# ARMv8M-Baseline register map
Registers are read-only, no defined reset value unless marked. A register's access mark holds for its fields unless they carry their own. Offsets are from the block's base; [hi:lo] are bit positions; {n}, {i} and the like mark numbered series.

## SCB — System Control Block
Base 0xE000ED00
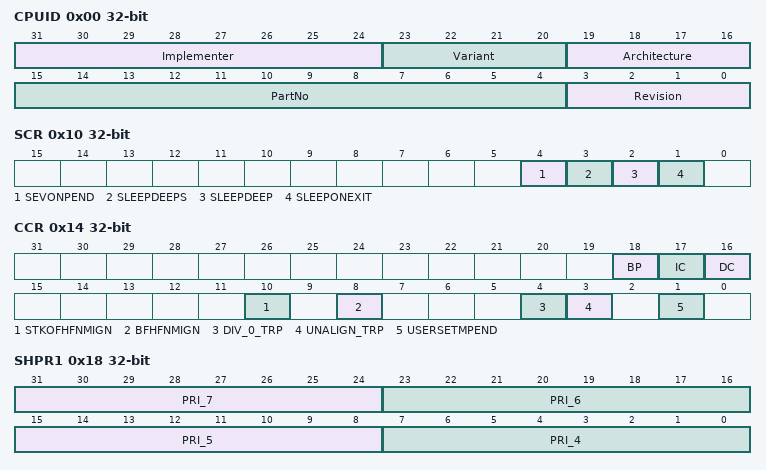
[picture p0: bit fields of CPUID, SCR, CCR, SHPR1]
0x00 CPUID — CPUID Base Register provides identification information for the PE, including an implementer code for the device and a device ID number
  [31:24] Implementer — Implementer code. This field must hold an implementer code that has been assigned by ARM
    65='A': ARM Limited
  [23:20] Variant — Variant number. IMPLEMENTATION DEFINED variant number
  [19:16] Architecture — Architecture version. Defines the Architecture implemented by the PE
    12=ARMv8-M architecture without Main Extension; 15=ARMv8-M architecture with Main Extension
  [15:4] PartNo — Part number. IMPLEMENTATION DEFINED primary part number for the device
  [3:0] Revision — Revision number. IMPLEMENTATION DEFINED revision number for the device
0x04 ICSR rw — Interrupt Control and State Register controls and provides status information for NMI, PendSV, SysTick and interrupts
  [31] PENDNMISET — Pend NMI set. Allows the NMI exception to be set as pending
    0=No effect; 1=Sets the NMI exception pending
  [31] PENDNMISET — Pend NMI set. Indicates whether the NMI exception is pending
    0=NMI exception not pending; 1=NMI exception pending
  [30] PENDNMICLR — Pend NMI clear. Allows the NMI exception pend state to be cleared
    0=No effect; 1=Clear pending status
  [28] PENDSVSET — Pend PendSV set. Allows the PendSV exception for the selected Security state to be set as pending
    0=No effect; 1=Sets the PendSV exception pending
  [28] PENDSVSET — Pend PendSV set. Indicates whether the PendSV for the selected Security state exception is pending
    0=PendSV exception not pending; 1=PendSV exception pending
  [27] PENDSVCLR — Pend PendSV clear
    0=No effect; 1=Clear pending status
  [26] PENDSTSET — Pend SysTick set. Allows the SysTick for the selected Security state exception to be set as pending
    0=No effect; 1=Sets the SysTick exception for the selected Security state pending
  [26] PENDSTSET — Pend SysTick set. Indicates whether the SysTick for the selected Security state exception is pending
    0=SysTick exception not pending; 1=SysTick exception pending
  [25] PENDSTCLR — Pend SysTick clear
    0=No effect; 1=Clear pending status
  [24] STTNS — SysTick Targets Non-secure
    0=SysTick is Secure; 1=SysTick is Non-secure
  [23] ISRPREEMPT — Interrupt preempt
    0=Will not service; 1=Will service a pending exception
  [22] ISRPENDING — Interrupt pending. Indicates whether an external interrupt, generated by the NVIC, is pending
    0=No external interrupt pending; 1=External interrupt pending
  [20:12] VECTPENDING — Vector pending. The exception number of the highest priority pending and enabled interrupt
  [11] RETTOBASE — Return to base. In Handler mode, indicates whether there is more than one active exception
    0=There is more than one active exception; 1=There is only one active exception
  [8:0] VECTACTIVE — Vector active. The exception number of the current executing exception
0x08 VTOR rw — Vector Table Offset Register holds the vector table address for the selected Security state
0x0C AIRCR rw — Application Interrupt and Reset Control Register sets or returns interrupt control and reset configuration
  [31:16] VECTKEY — Vector key. Writes to the AIRCR must be accompanied by a write of the value 0x05FA to this field
    0x5FA=Permit write to AIRCR fields
  [31:16] VECTKEYSTAT — Vector key status. Returns the bitwise inverse of the value required to be written to VECTKEY
  [15] ENDIANNESS — Data endianness. Indicates how the PE interprets the memory system data endianness
    0=Little-endian; 1=Big-endian
  [14] PRIS — Prioritize Secure exceptions
    0=Priority ranges of Secure and Non-secure exceptions are identical; 1=Non-secure exceptions are de-prioritized
  [13] BFHFNMINS — BusFault, HardFault, and NMI Non-secure enable
    0=BusFault, HardFault, and NMI are Secure; 1=BusFault and NMI are Non-secure and exceptions can target Non-secure HardFault
  [10:8] PRIGROUP — Priority grouping
    0=Group priority [7:1], subpriority [0]; {v}=Group priority [7:{v+1}], subpriority [{v}:0] (v=1..5)
  [3] SYSRESETREQS — System reset request Secure only
    0=SYSRESETREQ functionality is available to both Security states; 1=SYSRESETREQ functionality is only available to Secure state
  [2] SYSRESETREQ — System reset request. This bit allows software or a debugger to request a system reset
    0=Do not request a system reset; 1=Request a system reset
  [1] VECTCLRACTIVE — Clear active state
    0=Do not clear active state; 1=Clear active state
0x10 SCR rw — System Control Register sets or returns system control data
  [4] SEVONPEND — Send event on pend
    0=Transitions from inactive to pending are not wakeup events; 1=Transitions from inactive to pending are wakeup events
  [3] SLEEPDEEPS — Sleep deep secure
    0=The SLEEPDEEP bit accessible from both Security states; 1=The SLEEPDEEP bit behaves as RAZ/WI when accessed from the Non-secure state
  [2] SLEEPDEEP — Sleep deep. Provides a qualifying hint indicating that waking from sleep might take longer
    0=Selected sleep state is not deep sleep; 1=Selected sleep state is deep sleep
  [1] SLEEPONEXIT
    0=Enter sleep state disabled; 1=Enter sleep state permitted
0x14 CCR rw — Configuration and Control Register sets or returns configuration and control data
  [18] BP — Branch prediction enable. Enables program flow prediction for the selected Security state
    0=Program flow prediction disabled for the selected Security state; 1=Program flow prediction enabled for the selected Security state
  [17] IC — Instruction cache enable. This is a global enable bit for instruction caches in the selected Security state.
    0=Instruction caches disabled for the selected Security state; 1=Instruction caches enabled for the selected Security state
  [16] DC — Data cache enable. Enables data caching of all data accesses to Normal memory for the selected security state
    0=Data caching disabled for the selected Security state; 1=Data caching enabled for the selected Security state
  [10] STKOFHFNMIGN — Stack overflow in HardFault and NMI ignore. Controls the effect of a stack limit violation while executing at a requested priority less than 0 for the Security state with which the stack limit register is associated
    0=Stack limit faults not ignored; 1=Stack limit faults at requested priorities of less than 0 ignored
  [8] BFHFNMIGN — BusFault in HardFault or NMI ignore. Determines the effect of precise BusFaults on handlers running at a requested priority less than 0
    0=Precise BusFaults not ignored; 1=Precise BusFaults at requested priorities of less than 0 ignored
  [4] DIV_0_TRP — Divide by zero trap. Controls the generation of a DIVBYZERO UsageFault when attempting to perform integer division by zero
    0=DIVBYZERO UsageFault generation disabled; 1=DIVBYZERO UsageFault generation enabled
  [3] UNALIGN_TRP — Unaligned trap. Controls the trapping of unaligned word or halfword accesses
    0=Unaligned accesses permitted from LDR, LDRH, STR, and STRH; 1=Any unaligned transaction generates an UNALIGNED UsageFault
  [1] USERSETMPEND — User set main pending. Determines whether unprivileged accesses are permitted to pend interrupts via the STIR
    0=Unprivileged accesses to the STIR generate a fault; 1=Unprivileged accesses to the STIR are permitted
0x18 SHPR1 rw — System Handler Priority Register 1 sets or returns priority for system handlers 4 - 7
  [31:24] PRI_7 — Priority 7. Priority of system handler 7, SecureFault
  [23:16] PRI_6 — Priority 6. Priority of system handler 6, UsageFault
  [15:8] PRI_5 — Priority 5. Priority of system handler 5, BusFault
  [7:0] PRI_4 — Priority 4. Priority of system handler 4, MemManage
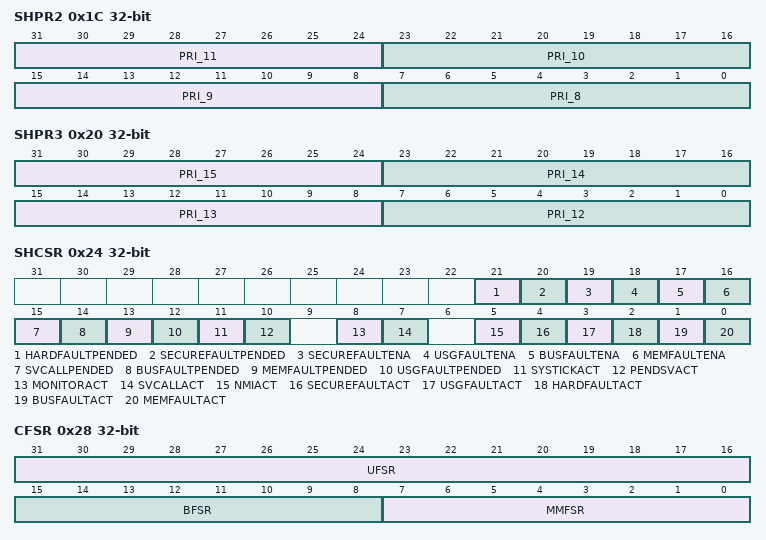
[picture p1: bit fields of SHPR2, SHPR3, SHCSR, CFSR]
0x1C SHPR2 rw — System Handler Priority Register 2 sets or returns priority for system handlers 8 - 11
  [31:24] PRI_11 — Priority 11. Priority of system handler 11, SVCall
  [23:16] PRI_10 — Reserved, RES0
  [15:8] PRI_9 — Reserved, RES0
  [7:0] PRI_8 — Reserved, RES0
0x20 SHPR3 rw — System Handler Priority Register 3 sets or returns priority for system handlers 12 - 15
  [31:24] PRI_15 — Priority 15. Priority of system handler 15, SysTick
  [23:16] PRI_14 — Priority 14. Priority of system handler 14, PendSV
  [15:8] PRI_13 — Reserved, RES0
  [7:0] PRI_12 — Priority 12. Priority of system handler 12, DebugMonitor
0x24 SHCSR rw — System Handler Control and State Register provides access to the active and pending status of system exceptions
  [21] HARDFAULTPENDED — HardFault exception pended state
    0=HardFault exception not pending for the selected Security state; 1=HardFault exception pending for the selected Security state
  [20] SECUREFAULTPENDED — SecureFault exception pended state
    0=SecureFault exception not pending; 1=SecureFault exception pending
  [19] SECUREFAULTENA — SecureFault exception enable
    0=SecureFault exception disabled; 1=SecureFault exception enabled
  [18] USGFAULTENA — UsageFault exception enable
    0=UsageFault exception disabled for the selected Security state; 1=UsageFault exception enabled for the selected Security state
  [17] BUSFAULTENA — BusFault exception enable. The value of this bit defines whether the BusFault exception is enabled
    0=BusFault exception disabled; 1=BusFault exception enabled
  [16] MEMFAULTENA — MemManage exception enable
    0=MemManage exception disabled for the selected Security state; 1=MemManage exception enabled for the selected Security state
  [15] SVCALLPENDED — SVCall exception pended state
    0=SVCall exception not pending for the selected Security state; 1=SVCall exception pending for the selected Security state
  [14] BUSFAULTPENDED — BusFault exception pended state
    0=BusFault exception not pending; 1=BusFault exception pending
  [13] MEMFAULTPENDED — MemManage exception pended state
    0=MemManage exception not pending for the selected Security state; 1=MemManage exception pending for the selected Security state
  [12] USGFAULTPENDED — UsageFault exception pended state
    0=UsageFault exception not pending for the selected Security state; 1=UsageFault exception pending for the selected Security state
  [11] SYSTICKACT — SysTick exception active state
    0=SysTick exception not active for the selected Security state; 1=SysTick exception active for the selected Security state
  [10] PENDSVACT — PendSV exception active state
    0=PendSV exception not active for the selected Security state; 1=PendSV exception active for the selected Security state
  [8] MONITORACT — DebugMonitor exception active state
    0=DebugMonitor exception not active; 1=DebugMonitor exception active
  [7] SVCALLACT — SVCall exception active state
    0=SVCall exception not active for the selected Security state; 1=SVCall exception active for the selected Security state
  [5] NMIACT — NMI exception active state
    0=NMI exception not active; 1=NMI exception active
  [4] SECUREFAULTACT — SecureFault exception active state
    0=SecureFault exception not active; 1=SecureFault exception active
  [3] USGFAULTACT — UsageFault exception active state for the selected Security state
    0=UsageFault exception not active for the selected Security state; 1=UsageFault exception active for the selected Security state
  [2] HARDFAULTACT — HardFault exception active state
    0=HardFault exception not active for the selected Security state; 1=HardFault exception active for the selected Security state
  [1] BUSFAULTACT — BusFault exception active state
    0=BusFault exception not active; 1=BusFault exception active
  [0] MEMFAULTACT — MemManage exception active state for the selected Security state
    0=MemManage exception not active for the selected Security state; 1=MemManage exception active for the selected Security state
0x28 CFSR rw — Configurable Fault Status Register contains the three Configurable Fault Status Registers
  [31:16] UFSR — UsageFault Status Register. Provides information on UsageFault exceptions
  [15:8] BFSR — BusFault Status Register. Provides information on BusFault exceptions
  [7:0] MMFSR — MemManage Fault Status Register. Provides information on MemManage exceptions
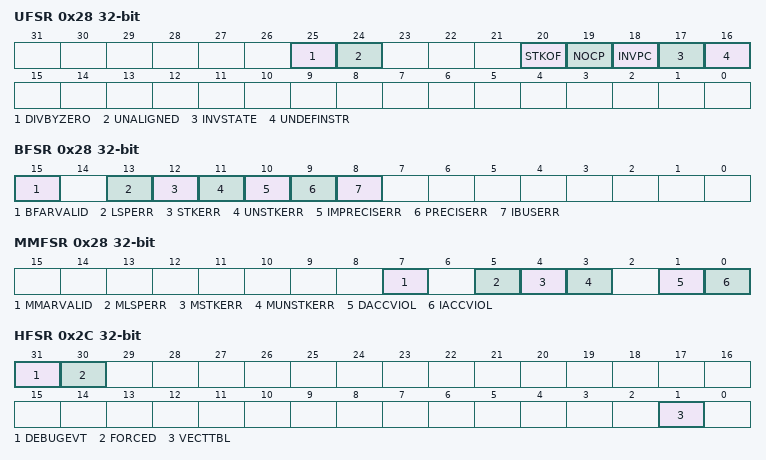
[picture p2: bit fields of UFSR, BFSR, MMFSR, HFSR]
0x28 UFSR rw — Usage Fault Status Register provides information on UsageFault exceptions
  [all] fields
    0=Error has not occurred; 1=Error has occurred
  [25] DIVBYZERO — Divide by zero flag. Indicates whether an integer division by zero error has occurred
  [24] UNALIGNED — Unaligned access flag. Indicates whether an unaligned access error has occurred
  [20] STKOF — Stack overflow flag. Indicates whether a stack overflow error has occurred
  [19] NOCP — No coprocessor flag. Indicates whether a coprocessor disabled or not present error has occurred
  [18] INVPC — Invalid PC flag. Indicates whether an integrity check error has occurred
  [17] INVSTATE — Invalid state flag. Indicates whether an EPSR.T or EPSR.IT validity error has occurred
  [16] UNDEFINSTR — Undefined instruction flag. Indicates whether an undefined instruction error has occurred
0x28 BFSR rw — Bus Fault Status Register provides information on BusFault exceptions
  [15] BFARVALID — BFAR valid. Indicates validity of the contents of the BFAR register
    0=BFAR content not valid; 1=BFAR content valid
  [13] LSPERR — Lazy state preservation error. Records whether a BusFault occurred during FP lazy state preservation
    0=No BusFault occurred during FP lazy state preservation; 1=BusFault occurred during FP lazy state preservation
  [12] STKERR — Stack error. Records whether a derived BusFault occurred during exception entry stacking
    0=No derived BusFault occurred; 1=Derived BusFault occurred during exception entry
  [11] UNSTKERR — Unstack error. Records whether a derived BusFault occurred during exception return unstacking
    0=No derived BusFault occurred; 1=Derived BusFault occurred during exception return
  [10] IMPRECISERR — Imprecise error. Records whether an imprecise data access error has occurred
    0=No imprecise data access error has occurred; 1=Imprecise data access error has occurred
  [9] PRECISERR — Precise error. Records whether a precise data access error has occurred
    0=No precise data access error has occurred; 1=Precise data access error has occurred
  [8] IBUSERR — Instruction bus error. Records whether a BusFault on an instruction prefetch has occurred
    0=No BusFault on instruction prefetch has occurred; 1=A BusFault on an instruction prefetch has occurred
0x28 MMFSR rw — MemManage Fault Status Register provides information on MemManage exceptions
  [7] MMARVALID — MMFAR valid flag. Indicates validity of the MMFAR register
    0=MMFAR content not valid; 1=MMFAR content valid
  [5] MLSPERR — MemManage lazy state preservation error flag. Records whether a MemManage fault occurred during FP lazy state preservation
    0=No MemManage occurred during FP lazy state preservation; 1=MemManage occurred during FP lazy state preservation
  [4] MSTKERR — MemManage stacking error flag. Records whether a derived MemManage fault occurred during exception entry stacking
    0=No derived MemManage occurred; 1=Derived MemManage occurred during exception entry
  [3] MUNSTKERR — MemManage unstacking error flag. Records whether a derived MemManage fault occurred during exception return unstacking
    0=No derived MemManage fault occurred; 1=Derived MemManage fault occurred during exception return
  [1] DACCVIOL — Data access violation flag. Records whether a data access violation has occurred
    0=No MemManage fault on data access has occurred; 1=MemManage fault on data access has occurred
  [0] IACCVIOL — Instruction access violation. Records whether an instruction related memory access violation has occurred
    0=No MemManage fault on instruction access has occurred; 1=MemManage fault on instruction access has occurred
0x2C HFSR rw — HardFault Status Register shows the cause of any HardFaults
  [31] DEBUGEVT — Debug event. Indicates when a debug event has occurred
    0=No debug event has occurred; 1=Debug event has occurred. The Debug Fault Status Register has been updated
  [30] FORCED
    0=No priority escalation has occurred; 1=Processor has escalated a configurable-priority exception to HardFault
  [1] VECTTBL — Vector table
    0=No vector table read fault has occurred
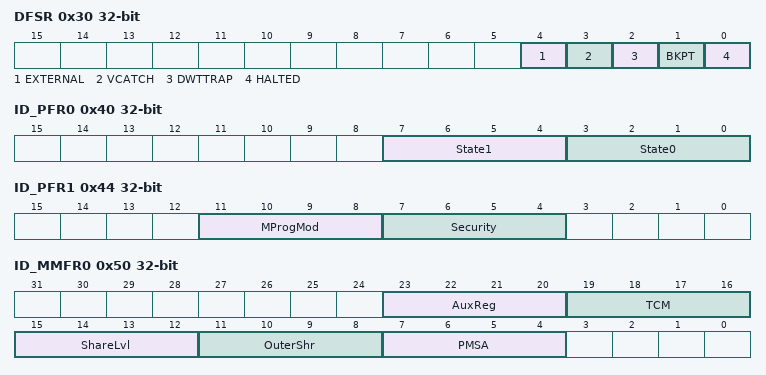
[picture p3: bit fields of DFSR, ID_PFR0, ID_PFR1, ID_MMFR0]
0x30 DFSR rw — Debug Fault Status Register shows which debug event occurred
  [all] fields
    0=Debug event has not occurred; 1=Debug event has occurred
  [4] EXTERNAL — External event. Indicates whether an External debug request debug event has occurred
  [3] VCATCH — Vector Catch event. Indicates whether a Vector catch debug event has occurred
  [2] DWTTRAP — Watchpoint event. Indicates whether a Watchpoint debug event has occurred
  [1] BKPT — Breakpoint event. Indicates whether a breakpoint debug event has occurred
  [0] HALTED — Halt or step event
0x34 MMFAR rw — MemManage Fault Address Register shows the address of the memory location that caused an MPU fault
  [31:0] ADDRESS — Data address for an MemManage fault
0x38 BFAR rw — BusFault Address Register shows the address associated with a precise data access BusFault
0x3C AFSR rw — Auxiliary Fault Status Register provides IMPLEMENTATION DEFINED fault status information
  [31:0] IMPLEMENTATION DEFINED — IMPLEMENTATION DEFINED. The contents of this field are IMPLEMENTATION DEFINED
0x40 ID_PFR0 — Processor Feature Register 0 gives top-level information about the instruction set supported by the PE
  [7:4] State1 — State one. T32 instruction set support
    3=T32 instruction set including Thumb-2 Technology implemented
  [3:0] State0 — State two. A32 instruction set support
    0=A32 instruction set not implemented
0x44 ID_PFR1 — Processor Feature Register 1 gives information about the programmers' model and Extensions support
  [11:8] MProgMod — M programmers' model. Identifies support for the M-Profile programmers' model support
    2=Two-stack programmers' model
  [7:4] Security — Security. Identifies whether the Security Extension is implemented
    0=Security Extension not implemented; 1=Security Extension implemented
0x48 ID_DFR0 — Debug Feature Register 0 provides top level information about the debug system
  [23:20] MProfDbg — M-profile debug. Indicates the supported M-profile debug architecture
    0=Halting debug is not implemented; 2=ARMv8-M Debug architecture
0x4C ID_AFR0 — Auxiliary Feature Register 0 provides information about the IMPLEMENTATION DEFINED features of the PE
  [0] IMPDEFm — IMPLEMENTATION DEFINED. IMPLEMENTATION DEFINED meaning
0x50 ID_MMFR0 — Memory Model Feature Register 0 provides information about the implemented memory model and memory management support
  [23:20] AuxReg — Auxiliary Registers. Indicates support for Auxiliary Control Registers
    0=No Auxiliary Control Registers; 1=Auxiliary Control Registers supported
  [19:16] TCM — Tightly coupled memories. Indicates support for tightly coupled memories (TCMs)
    0=None supported; 1=TCMs supported with IMPLEMENTATION DEFINED control
  [15:12] ShareLvl — Shareability Levels. Indicates the number of shareability levels implemented
    0=One level of shareability implemented; 1=Two levels of shareability implemented
  [11:8] OuterShr — Outermost Shareability. Indicates the outermost shareability domain implemented
    0=Implemented as Non-cacheable; 1=Implemented with hardware coherency support; 15=Shareability ignored
  [7:4] PMSA — Protected memory system architecture
    4=Supports PMSAv8
0x54 ID_MMFR1 — Memory Model Feature Register 1 provides information about the implemented memory model and memory management support
0x58 ID_MMFR2 — Memory Model Feature Register 2 provides information about the implemented memory model and memory management support
  [27:24] WFIStall — WFI stall. Indicates the support for Wait For Interrupt (WFI) stalling
    0=WFI never stalls; 1=WFI has the ability to stall
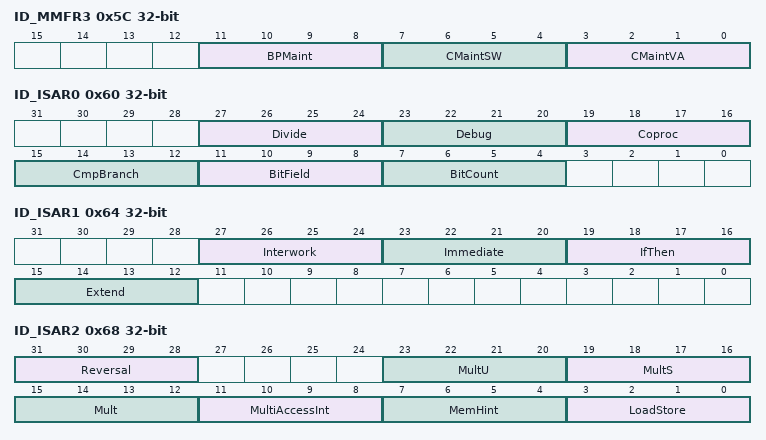
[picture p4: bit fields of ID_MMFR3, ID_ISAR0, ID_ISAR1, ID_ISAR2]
0x5C ID_MMFR3 — Memory Model Feature Register 3 provides information about the implemented memory model and memory management support
  [11:8] BPMaint — Branch predictor maintenance. Indicates the supported branch predictor maintenance
    0=None supported; 1=Support for invalidate all of branch predictors
  [7:4] CMaintSW — Cache maintenance set/way. Indicates the supported cache maintenance operations by set/way
    0=None supported; 1=Maintenance by set/way operations supported
  [3:0] CMaintVA — Cache maintenance by address. Indicates the supported cache maintenance operations by address
    0=None supported; 1=Maintenance by address and instruction cache invalidate all supported
0x60 ID_ISAR0 — Instruction Set Attribute Register 0 provides information about the instruction set implemented by the PE
  [27:24] Divide — Divide. Indicates the supported Divide instructions
    1=Supports SDIV and UDIV instructions
  [23:20] Debug — Debug. Indicates the implemented Debug instructions
    1=Supports BKPT instruction
  [19:16] Coproc — Coprocessor. Indicates the supported Coprocessor instructions
    0=No coprocessor instructions support other than FPU; 4=Coprocessor instructions supported; 0=3RES04 7BitCount8 11BitField12 15CmpBranch16 19Coproc20 23Debug24 27Divide28 31RES0D1 Register Specification D1
  [15:12] CmpBranch — Compare and branch. Indicates the supported combined Compare and Branch instructions
    1=Supports CBNZ and CBZ instructions
  [11:8] BitField — Bit field. Indicates the supported bit field instructions
    1=BFC, BFI, SBFX, and UBFX supported
  [7:4] BitCount — Bit count. Indicates the supported bit count instructions
    1=CLZ supported
0x64 ID_ISAR1 — Instruction Set Attribute Register 1 provides information about the instruction set implemented by the PE
  [27:24] Interwork — Interworking. Indicates the implemented interworking instructions
    2=BLX, BX, and loads to PC interwork
  [23:20] Immediate — Immediate. Indicates the implemented for data-processing instructions with long immediates
    2=ADDW, MOVW, MOVT, and SUBW supported
  [19:16] IfThen — If-Then. Indicates the implemented If-Then instructions
    1=IT instruction supported
  [15:12] Extend — Extend. Indicates the implemented Extend instructions
    1=SXTB, SXTH, UXTB, and UXTH; 2=Adds SXTB16, SXTAB, SXTAB16, SXTAH, UXTB16, UXTAB, UXTAB16, and UXTAH, DSP Extension only
0x68 ID_ISAR2 — Instruction Set Attribute Register 2 provides information about the instruction set implemented by the PE
  [31:28] Reversal — Reversal. Indicates the implemented Reversal instructions
    2=REV, REV16, REVSH and RBIT instructions supported
  [23:20] MultU — Multiply unsigned. Indicates the implemented advanced unsigned Multiply instructions
    1=UMULL and UMLAL; 2=Adds UMAAL, DSP Extension only
  [19:16] MultS — Multiply signed. Indicates the implemented advanced signed Multiply instructions
    1=SMULL and SMLAL; 3=Adds all saturating and DSP signed multiplies, DSP Extension only
  [15:12] Mult — Multiplies. Indicates the implemented additional Multiply instructions
    2=MUL, MLA, and MLS
  [11:8] MultiAccessInt — Multi-access instructions. Indicates the support for interruptible multi-access instructions
    0=No support. LDM and STM instructions are not interruptible; 1=LDM and STM instructions are restartable; 2=LDM and STM instructions are continuable
  [7:4] MemHint — Memory hints. Indicates the implemented Memory hint instructions
    3=PLI and PLD instructions implemented
  [3:0] LoadStore — Load/store. Indicates the implemented additional load/store instructions
    2=Supports load-acquire, store-release, and exclusive load and store instructions
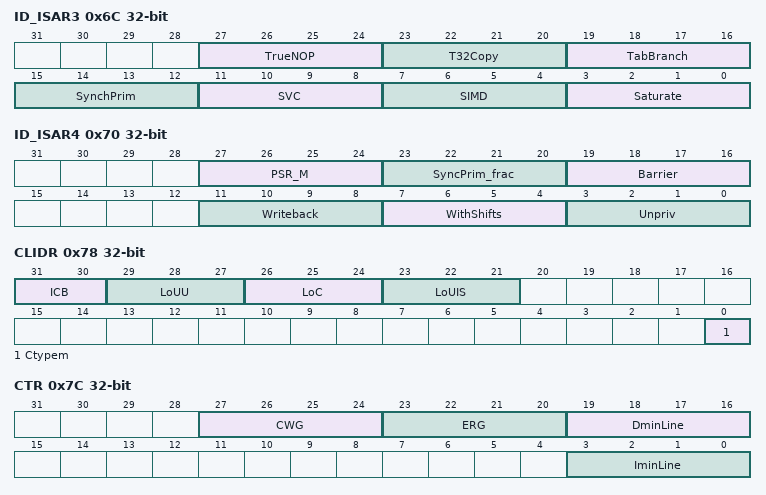
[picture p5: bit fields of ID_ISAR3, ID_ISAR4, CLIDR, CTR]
0x6C ID_ISAR3 — Instruction Set Attribute Register 3 provides information about the instruction set implemented by the PE
  [27:24] TrueNOP — True no-operation. Indicates the implemented true NOP instructions
    1=NOP instruction and compatible hints implemented
  [23:20] T32Copy — T32 copy. Indicates the support for T32 non flag-setting MOV instructions
    1=Encoding T1 of MOV (register) supports copying low register to low register
  [19:16] TabBranch — Table branch. Indicates the implemented Table Branch instructions
    1=TBB and TBH implemented
  [15:12] SynchPrim — Synchronization primitives. Used in conjunction with ID_ISAR4
    1=LDREX, STREX, LDREXB, STREXB, LDREXH, STREXH, and CLREX implemented
  [11:8] SVC — Supervisor call. Indicates the implemented SVC instructions
    1=SVC instruction implemented
  [7:4] SIMD — Single-instruction, multiple-data. Indicates the implemented SIMD instructions
    1=SSAT, USAT, and Q-bit implemented; 3=Adds all packed arithmetic and GE-bits, DSP Extension only
  [3:0] Saturate — Saturate. Indicates the implemented saturating instructions
    0=None implemented; 1=QADD, QDADD, QDSUB, QSUB, and Q-bit implemented, DSP Extension only
0x70 ID_ISAR4 — Instruction Set Attribute Register 4 provides information about the instruction set implemented by the PE
  [27:24] PSR_M — Program Status Registers M. Indicates the implemented M profile instructions to modify the PSRs
    1=M profile forms of CPS, MRS, and MSR implemented
  [23:20] SyncPrim_frac — Synchronization primitives fractional. Used in conjunction with ID_ISAR3
    3=LDREX, STREX, CLREX, LDREXB, LDREXH, STREXB, and STREXH implemented
  [19:16] Barrier — Barrier. Indicates the implemented Barrier instructions
    1=DMB, DSB, and ISB barrier instructions implemented
  [11:8] Writeback — Writeback. Indicates the support for writeback addressing modes
    1=All writeback addressing modes supported
  [7:4] WithShifts — With shifts. Indicates the support for writeback addressing modes
    3=Support for constant shifts on load/store and other instructions
  [3:0] Unpriv — Unprivileged. Indicates the implemented unprivileged instructions
    2=LDRBT, LDRHT, LDRSBT, LDRSHT, LDRT, STRBT, STRHT, and STRT implemented
0x74 ID_ISAR5 — Instruction Set Attribute Register 5 provides information about the instruction set implemented by the PE
0x78 CLIDR — Cache Level ID Register identifies the type of caches implemented and the level of coherency and unification
  [31:30] ICB — Inner cache boundary. This field indicates the boundary between inner and outer domain
    0=Not disclosed in this mechanism; 1=L1 cache is the highest inner level; 2=L2 cache is the highest inner level; 3=L3 cache is the highest inner level
  [29:27] LoUU — Level of Unification Uniprocessor
  [26:24] LoC — Level of Coherence. This field indicates the Level of Coherence for the cache hierarchy
  [23:21] LoUIS — Level of Unification Inner Shareable
  [0] Ctypem — Cache type field m. Indicates the type of cache implemented at level m
    0=No cache; 1=Instruction cache only; 2=Data cache only; 3=Separate Instruction And Data Caches; 4=Unified cache
0x7C CTR — Cache Type Register provides information about the architecture of the caches
  [27:24] CWG — Cache Writeback Granule
    0=Indicates that this register does not provide Cache Writeback Granule information and either the architectural maximum of 512 w
  [23:20] ERG — Exclusives Reservation Granule
    0=Indicates that this register does not provide Exclusives Reservation Granule information and the architectural maximum of 512 w
  [19:16] DminLine — Data cache minimum line length
  [3:0] IminLine — Instruction cache minimum line length
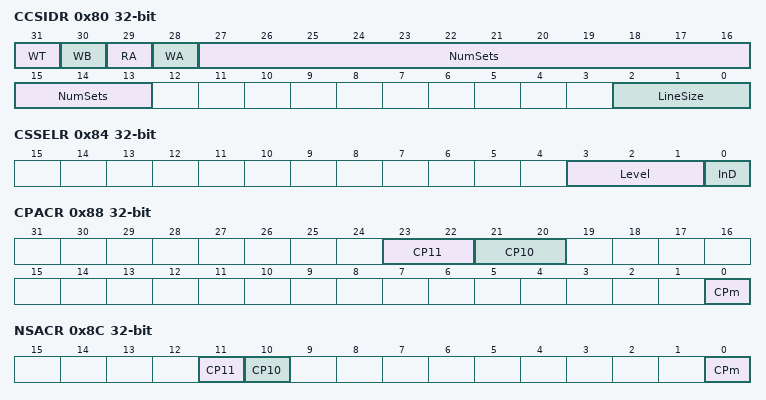
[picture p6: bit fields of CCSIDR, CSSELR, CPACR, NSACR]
0x80 CCSIDR — Current Cache Size ID register the CCSIDR provides information about the architecture of the currently selected cache
  [31] WT — Write-Through. Indicates whether the currently selected cache level supports Write-Through
    0=Not supported; 1=Supported
  [30] WB — Writeback. Indicates whether the currently selected cache level supports writeback
    0=Not supported; 1=Supported
  [29] RA — Read-allocate. Indicates whether the currently selected cache level supports read-allocation
    0=Not supported; 1=Supported
  [28] WA — Write-Allocate. Indicates whether the currently selected cache level supports write-allocation
    0=Not supported; 1=Supported
  [27:13] NumSets — Number of sets. Indicates (Number of sets in the currently selected cache) - 1
  [2:0] LineSize — Line size. Indicates (Log2(Number of words per line in the currently selected cache)) - 2
0x84 CSSELR rw — Cache Size Selection Register selects the current Cache Size ID Register, CCSIDR, by specifying the required cache level and the cache type (either instruction or data cache)
  [3:1] Level — Cache level. Selects which cache level is to be identified
    {v}=Level {v+1} cache (v=0..6)
  [0] InD — Instruction not data. Selects whether the instruction or the data cache is to be identified
    0=Data or unified cache; 1=Instruction cache
0x88 CPACR rw — Coprocessor Access Control Register specifies the access privileges for coprocessors and the FP Extension
  [23:22] CP11 — CP11 Privilege. The value in this field is ignored
  [21:20] CP10 — CP10 Privilege. Defines the access rights for the floating-point functionality
    0=All accesses to the FP Extension result in NOCP UsageFault; 1=Unprivileged accesses to the FP Extension result in NOCP UsageFault; 3=Full access to the FP Extension
  [0] CPm — Coprocessor m privilege. Controls access privileges for coprocessor m
    0=Access denied. Any attempted access generates a NOCP UsageFault; 1=Privileged access only. An unprivileged access generates a NOCP UsageFault; 3=Full Access
0x8C NSACR rw — Non-secure Access Control Register defines the Non-secure access permissions for both the FP Extension and coprocessors CP0 to CP7
  [11] CP11 — CP11 access. Enables Non-secure access to the Floating-point Extension
  [10] CP10 — CP10 access. Enables Non-secure access to the Floating-point Extension
    0=Non-secure accesses to the Floating-point Extension generate a NOCP UsageFault; 1=Non-secure access to the Floating-point Extension permitted
  [0] CPm — CPm access. Enables Non-secure access to coprocessor CPm
    0=Non-secure accesses to this coprocessor generate a NOCP UsageFault; 1=Non-secure access to this coprocessor permitted
